# STM32MP13xx register map
File version: 1.5
CPU: CA7 r0p0, little endian, MPU, FPU, 4 interrupt priority bits
Registers are 32-bit, read-write, reset 0x0 unless marked. A register's access mark holds for its fields unless they carry their own. Offsets are from the block's base; [hi:lo] are bit positions; {n}, {i} and the like mark numbered series; 'fields as' and 'values as' point back to an identical list.

## DDRPHYC (part 2 of 2)
Base 0x5A004000
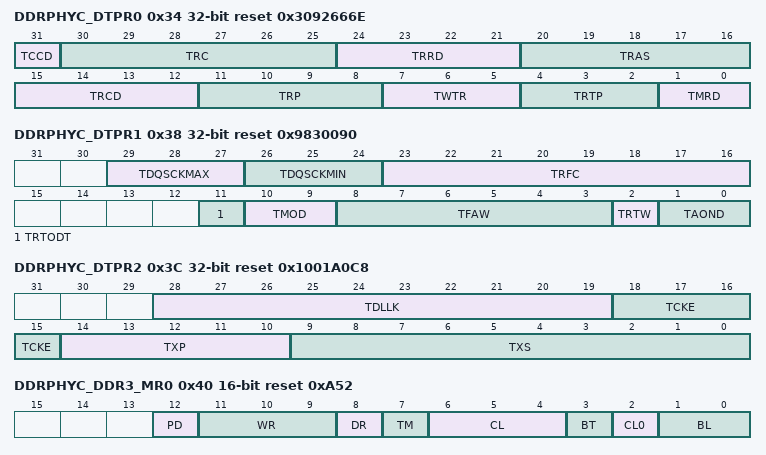
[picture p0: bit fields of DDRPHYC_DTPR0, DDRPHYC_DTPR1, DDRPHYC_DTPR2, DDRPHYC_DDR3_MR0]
0x34 DDRPHYC_DTPR0 reset 0x3092666E — DDRPHYC DTP register 0
  [31] TCCD — tCCDRead to read and write to write command delay
    0=BL/2 for DDR2 and 4 for DDR3; 1=BL/2 + 1 for DDR2 and 5 for DDR3
  [30:25] TRC — tRC Activate to activate command delay (same bank). Valid values are 2 to 42.
  [24:21] TRRD — tRRD Activate to activate command delay (different banks). Valid values are 1 to 8.
  [20:16] TRAS — tRAS Activate to precharge command delay. Valid values are 2 to 31.
  [15:12] TRCD — tRCD Activate to read or write delay. Minimum time from when an activate command is issued to when a read or write to the activated row can be issued. Valid values are 2 to 11.
  [11:8] TRP — tRP Precharge command period: The minimum time between a precharge command and any other command. Note: Note that the controller automatically derives tRPA for 8-bank DDR2 devices by adding 1 to tRP. Valid values are 2 to 11.
  [7:5] TWTR — tWTR Internal write to read command delay. Valid values are 1 to 6.
  [4:2] TRTP — tRTP Internal read to precharge command delay. Valid values are 2 to 6. Note that even though RTP does not apply to JEDEC DDR devices, this parameter must still be set to a minimum value of 2 for DDR because the Controller always uses the DDR2 equation, AL + BL/2 + max(RTP,2) â 2, to compute the read to precharge timing (which is BL/2 for JEDEC DDR).
  [1:0] TMRD — tMRD Load mode cycle time: The minimum time between a load mode register command and any other command. For DDR3 this is the minimum time between two load mode register commands. For DDR3, the value used for tMRD is 4 plus the value programmed in these bits, i.e. tMRD value for DDR3 ranges from 4 to 7. For LPDDR3, the value used for tMRD is 8 plus the value programmed in these bits.
0x38 DDRPHYC_DTPR1 reset 0x9830090 — DDRPHYC DTP register 1
  [29:27] TDQSCKMAX — tDQSCKmax Maximum DQS output access time from CK/CK# (LPDDR2 only). This value is used for implementing read-to-write spacing. Valid values are 1 to 7.
  [26:24] TDQSCKMIN — tDQSCKmin DQS output access time from CK/CK# (LPDDR2/3 only). This value is used for computing the read latency. Valid values are 0 to 7. This value is derived from the corresponding parameter in the SDRAM datasheet divided by the clock cycle time without rounding up. The fractional remainder is automatically adjusted for by data training in quarter clock cycle units. If data training is not performed then this fractional remainder must be converted to quarter clock cycle units and the gating registers (DXnDQSTR) adjusted accordingly.
  [23:16] TRFC — tRFC Refresh-to-Refresh: Indicates the minimum time, in clock cycles, between two refresh commands or between a refresh and an active command. This is derived from the minimum refresh interval from the datasheet, tRFC(min), divided by the clock cycle time. The default number of clock cycles is for the largest JEDEC tRFC(min parameter value supported.
  [11] TRTODT — tRTODT Read to ODT delay (DDR3 only). Specifies whether ODT can be enabled immediately after the read post-amble or one clock delay has to be added. Valid values are: If tRTODT is set to 1, then the read-to-write latency is increased by 1 if ODT is enabled.
    0=ODT may be turned on immediately after read post-amble; 1=ODT may not be turned on until one clock after the read post-amble
  [10:9] TMOD — tMOD Load mode update delay (DDR3 only). The minimum time between a load mode register command and a non-load mode register command. Valid values are:
    {v}={v+12} (v=0..3)
  [8:3] TFAW — tFAW 4-bank activate period. No more than 4-bank activate commands may be issued in a given tFAW period. Only applies to 8-bank devices. Valid values are 2 to 31.
  [2] TRTW — tRTW Read to Write command delay. Valid values are: This parameter allows the user to increase the delay between issuing Write commands to the SDRAM when preceded by Read commands. This provides an option to increase bus turn-around margin for high frequency systems.
    0=standard bus turn around delay; 1=add 1 clock to standard bus turn around delay
  [1:0] TAOND — tAOND/tAOFD ODT turn-on/turn-off delays (DDR2 only). The delays are in clock cycles. Valid values are: Most DDR2 devices utilize a fixed value of 2/2.5. For non-standard SDRAMs, the user must ensure that the operational Write Latency is always greater than or equal to the ODT turn-on delay. For example, a DDR2 SDRAM with CAS latency set to 3 and CAS additive latency set to 0 has a Write Latency of 2. Thus 2/2.5 can be used, but not 3/3.5 or higher.
    0=2/2.5; 1=3/3.5; 2=4/4.5; 3=5/5.5
0x3C DDRPHYC_DTPR2 reset 0x1001A0C8 — DDRPHYC DTP register 2
  [28:19] TDLLK — tDLLK DLL locking time. Valid values are 2 to 1023.
  [18:15] TCKE — tCKE CKE minimum pulse width. Also specifies the minimum time that the SDRAM must remain in power down or self refresh mode. For DDR3 this parameter must be set to the value of tCKESR which is usually bigger than the value of tCKE. Valid values are 2 to 15.
  [14:10] TXP — tXP Power down exit delay. The minimum time between a power down exit command and any other command. This parameter must be set to the maximum of the various minimum power down exit delay parameters specified in the SDRAM datasheet, i.e. max(tXP, tXARD, tXARDS) for DDR2 and max(tXP, tXPDLL) for DDR3. Valid values are 2 to 31.
  [9:0] TXS — tXS Self refresh exit delay. The minimum time between a self refresh exit command and any other command. This parameter must be set to the maximum of the various minimum self refresh exit delay parameters specified in the SDRAM datasheet, i.e. max(tXSNR, tXSRD) for DDR2 and max(tXS, tXSDLL) for DDR3. Valid values are 2 to 1023.
0x40 DDRPHYC_DDR3_MR0 16-bit reset 0xA52 — DDRPHYC MR0 register for DDR3
  [12] PD — Power-down control Controls the exit time for power-down modes. Refer to SDRAM datasheet for details on power-down modes. Valid values are:
    0=Slow exit (DLL off); 1=Fast exit (DLL on)
  [11:9] WR — Write recovery This is the value of the write recovery in clock cycles. It is calculated by dividing the data sheet write recovery time, tWR (ns) by the data sheet clock cycle time, tCK (ns) and rounding up a non-integer value to the next integer. Valid values are: All other settings are reserved and should not be used. Note: tWR (ns) is the time from the first SDRAM positive clock edge after the last data-in pair of a write command, to when a precharge of the same bank can be issued.
    {v}={v+4} (v=1..4); 5=10; 6=12
  [8] DR — DLL reset (autoclear) Writing a '1â to this bit resets the SDRAM DLL. This bit is self clearing, i.e. it returns back to '0â after the DLL reset has been issued.
  [7] TM — Operating mode Selects either normal operating mode (0) or test mode (1). Test mode is reserved for the manufacturer and should not be used.
  [6:4] CL — CAS latency The delay, in clock cycles, between when the SDRAM registers a read command to when data is available. Valid values for CL[3:0] are: Others: Reserved
  [3] BT — Burst type Indicates whether a burst is sequential (0) or interleaved (1).
  [2] CL0 — CAS latency The delay, in clock cycles, between when the SDRAM registers a read command to when data is available. Valid values for CL[3:0] are: Others: Reserved
  [1:0] BL — Burst length Determines the maximum number of column locations that can be accessed during a given read or write command. Valid values for DDR3 are:
    0=8 (Fixed); 1=4 or 8 (On the fly); 2=4 (Fixed)
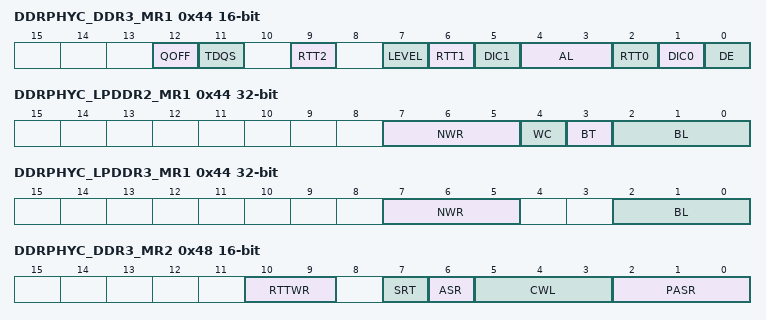
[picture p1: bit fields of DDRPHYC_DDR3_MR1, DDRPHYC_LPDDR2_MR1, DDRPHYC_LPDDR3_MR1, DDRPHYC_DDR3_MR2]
0x44 DDRPHYC_DDR3_MR1 16-bit — DDRPHYC MR1 register for DDR3
  [12] QOFF — Output enable/disable This feature is intended to be used for IDD characterization of read current and should not be used in normal operation.
    0=all outputs function as normal; 1=all SDRAM outputs are disabled removing output buffer current
  [11] TDQS — Termination data strobe When enabled ('1â) TDQS provides additional termination resistance outputs that may be useful in some system configurations. (N/A)
  [9] RTT2 — On die termination Selects the effective resistance for SDRAM on die termination. Valid values for {RTT2,RTT1,RTT0} are: Others: Reserved
  [7] LEVEL — Write leveling enable (N/A)
  [6] RTT1 — On die termination Selects the effective resistance for SDRAM on die termination. Valid values for {RTT2,RTT1,RTT0} are: Others: Reserved
  [5] DIC1 — Output driver impedance control Controls the output drive strength. Valid values for {DIC1,DIC0} are:
    0=RZQ/6; 1=RZQ/7
  [4:3] AL — Posted CAS Additive Latency: Setting additive latency that allows read and write commands to be issued to the SDRAM earlier than normal (refer to SDRAM datasheet for details). Valid values are:
    0=0 (AL disabled); 1=CL - 1; 2=CL - 2
  [2] RTT0 — On die termination Selects the effective resistance for SDRAM on die termination. Valid values for {RTT2,RTT1,RTT0} are: Others: Reserved
  [1] DIC0 — Output driver impedance control Controls the output drive strength. Valid values for {DIC1,DIC0} are:
    0=RZQ/6; 1=RZQ/7
  [0] DE — DLL enable/disable Enable (0) or disable (1) the DLL. DLL must be enabled for normal operation.
0x44 DDRPHYC_LPDDR2_MR1 (alternate view of DDRPHYC_DDR3_MR1)
  [7:5] NWR — Write recovery Others: Reserved
    1=nWR=3; 4=nWR=6; 6=nWR=8; 7=nWR=9
  [4] WC — Wrap control
    0=wrap; 1=no wrap
  [3] BT — Burst Type: Indicates whether a burst is sequential (0) or interleaved (1). ,
  [2:0] BL — Burst length Determines the maximum number of column locations that can be accessed during a given read or write command. Valid values are: Others: Reserved
    2=4; 3=8; 4=16
0x44 DDRPHYC_LPDDR3_MR1 (alternate view of DDRPHYC_DDR3_MR1)
  [7:5] NWR — Write recovery If nWRE (MR2 [4]) = 0: -001: nWR=3 -100: nWR=6 -110: nWR=8 -111: nWR=9 If nWRE (MR2[4]) = 1: -000: nWR=10 -001: nWR=11 -010: nWR=12 Others: Reserved
  [2:0] BL — Burst length Determines the maximum number of column locations that can be accessed during a given read or write command. Others: Reserved
    3=8
0x48 DDRPHYC_DDR3_MR2 16-bit — DDRPHYC MR2 register for DDR3
  [10:9] RTTWR — Dynamic ODT Selects RTT for dynamic ODT.
    0=Dynamic ODT off; 1=RZQ/4; 2=RZQ/2
  [7] SRT — Self-refresh temperature range Selects either normal ('0â) or extended ('1â) operating temperature range during self-refresh.
  [6] ASR — Auto self-refresh When enabled ('1â), SDRAM automatically provides self-refresh power management functions for all supported operating temperature values. Otherwise the SRT bit must be programmed to indicate the temperature range.
  [5:3] CWL — CAS write latency The delay, in clock cycles, between when the SDRAM registers a write command to when write data is available. Others: Reserved
    0=5 (tCK = 2.5ns); 1=6 (2.5ns > tCK = 1.875ns); 2=7 (1.875ns > tCK = 1.5ns); 3=8 (1.5ns > tCK = 1.25ns)
  [2:0] PASR — Partial array self-refresh Specifies that data located in areas of the array beyond the specified location are lost if self refresh is entered. Valid settings for 8 banks are:
    0=Full Array; 1=Half Array (BA[2:0] = 000, 001, 010 & 011); 2=Quarter Array (BA[2:0] = 000, 001); 3=1/8 Array (BA[2:0] = 000); 4=3/4 Array (BA[2:0] = 010, 011, 100, 101, 110 & 111); 5=Half Array (BA[2:0] = 100, 101, 110 & 111); 6=Quarter Array (BA[2:0] = 110 & 111); 7=1/8 Array (BA[2:0] 111)
0x48 DDRPHYC_LPDDR2_MR2 (alternate view of DDRPHYC_DDR3_MR2) — DDRPHYC MR2 register for LPDDR2
  [2:0] RLWL — Read and write latency Others: Reserved
    1=RL = 3 /WL = 1; 2=RL = 4 / WL = 2; 3=RL = 5 / WL = 2; 4=RL = 6 / WL = 3; 5=RL = 7 / WL = 4; 6=RL = 8 / WL = 4
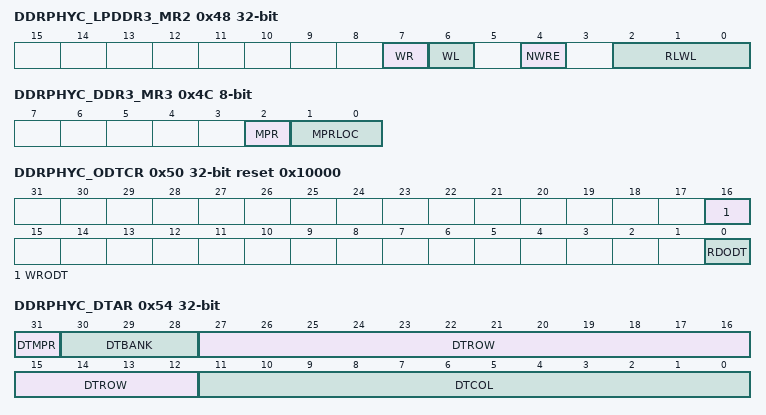
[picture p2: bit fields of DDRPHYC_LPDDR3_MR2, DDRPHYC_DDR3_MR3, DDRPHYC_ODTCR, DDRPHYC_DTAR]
0x48 DDRPHYC_LPDDR3_MR2 (alternate view of DDRPHYC_DDR3_MR2) — DDRPHYC MR2 register for LPDDR3
  [7] WR — New for LPDDR3 (not used by this PHY, leave at zero)
  [6] WL — New for LPDDR3 (not used by this PHY, leave at zero)
  [4] NWRE — New for LPDDR3 (not used by this PHY, leave at zero)
  [2:0] RLWL — Read and write latency Others: Reserved
    values as DDRPHYC_LPDDR2_MR2.RLWL
0x4C DDRPHYC_DDR3_MR3 8-bit — DDRPHYC MR3 register for DDR3
  [2] MPR — Multi-purpose register enable Enables, if set, that read data should come from the Multi-Purpose Register. Otherwise read data come from the DRAM array.
  [1:0] MPRLOC — Multi-purpose register (MPR) location Selects MPR data location. Others: Reserved
    0=Predefined pattern for system calibration
0x50 DDRPHYC_ODTCR reset 0x10000 — DDRPHYC ODTC register
  [16] WRODT — Specifies whether ODT should be enabled ('1â) or disabled ('0â) on write
  [0] RDODT — Specifies whether ODT should be enabled ('1â) or disabled ('0â) on read
0x54 DDRPHYC_DTAR — DDRPHYC DTA register
  [31] DTMPR — Data training using MPR (DDR3 Only): Specifies, if set, that data-training should use the SDRAM Multi-Purpose Register (MPR) register. Otherwise data-training is performed by first writing to some locations in the SDRAM and then reading the back.
  [30:28] DTBANK — Data training bank address: Selects the SDRAM bank address to be used during data training.
  [27:12] DTROW — Data training row address: Selects the SDRAM row address to be used during data training.
  [11:0] DTCOL — Data training column address: Selects the SDRAM column address to be used during data training. The lower four bits of this address must always be â0000â.
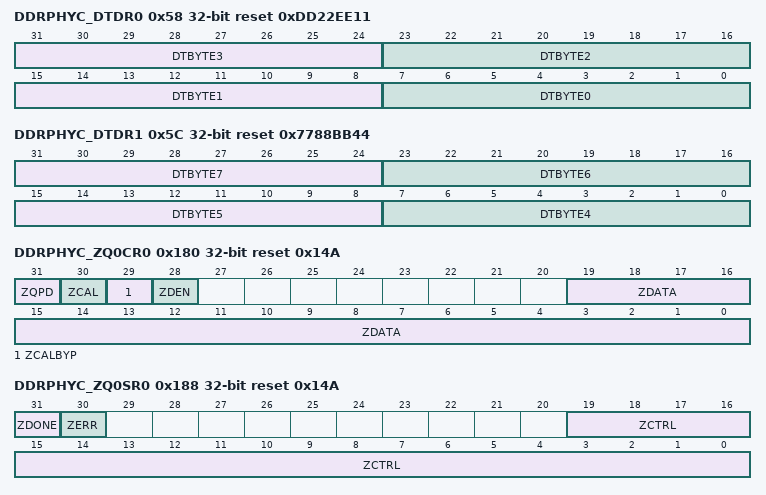
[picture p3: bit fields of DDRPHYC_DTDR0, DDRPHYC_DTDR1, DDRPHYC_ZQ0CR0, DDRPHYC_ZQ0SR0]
0x58 DDRPHYC_DTDR0 reset 0xDD22EE11 — DDRPHYC DTD register 0
  [31:24] DTBYTE3 — Data training data The first 4 bytes (e.g. shifted as Byte 0,1,2,3) of data used during data training. This same data byte is used for each Byte Lane. Default sequence is a walking 1 while toggling data every data cycle.
  [23:16] DTBYTE2 — Data Training Data
  [15:8] DTBYTE1 — Data Training Data
  [7:0] DTBYTE0 — Data Training Data
0x5C DDRPHYC_DTDR1 reset 0x7788BB44 — DDRPHYC DTD register 1
  [31:24] DTBYTE7 — Data training data: The second 4 bytes (e.g. shifted as Byte 4,5,6,7) of data used during data training. This same data byte is used for each Byte Lane. Default sequence is a walking 1 while toggling data every data cycle.
  [23:16] DTBYTE6 — Data Training Data
  [15:8] DTBYTE5 — Data Training Data
  [7:0] DTBYTE4 — Data Training Data
0x178 DDRPHYC_GPR0 — DDRPHYC general purpose register 0
  [31:0] GPR0 — General purpose register 0 bits
0x17C DDRPHYC_GPR1 — DDRPHYC general purpose register 1
  [31:0] GPR1 — General purpose register 1 bits
0x180 DDRPHYC_ZQ0CR0 reset 0x14A — DDRPHYC ZQ0C register 0
  [31] ZQPD — ZCAL power down Powers down, if set, the PZQ cell.
  [30] ZCAL — ZCAL trigger Impedance Calibration Trigger: A write of '1' to this bit triggers impedance calibration to be performed by the impedance control logic. The impedance calibration trigger bit is self-clearing and returns back to '0' when the calibration is complete. Note: If ZDEN is set, then the ZCAL bit should be set to 0.
  [29] ZCALBYP — Impedance calibration bypass Impedance Calibration Bypass: Disables, if set, impedance calibration of this ZQ control block when impedance calibration is triggered globally using the ZCAL bit of DDRPHYC_PIR. Impedance calibration of this ZQ block may be triggered manually using ZCAL.
  [28] ZDEN — Impedance override enable Impedance Over-ride Enable: When this bit is set, it allows users to directly drive the impedance control using the data programmed in the ZQDATA field. Otherwise, the control is generated automatically by the impedance control logic. Note: If ZDEN is set, then the ZCAL bit should be set to 0.
  [19:0] ZDATA — Impedance override Impedance Over-Ride Data: Data used to directly drive the impedance control. ZDATA field mapping for D3R I/Os is as follows: ZDATA[27:20] is reserved and returns zeros on reads ZDATA[19:15] is used to select the pull-up on-die termination impedance ZDATA[14:10] is used to select the pull-down on-die termination impedance ZDATA[9:5] is used to select the pull-up output impedance ZDATA[4:0] is used to select the pull-down output impedance Note: See mPHY ST40c25 Datasheet for ZDATA encoding, default value is: ODT pulp-up/down set to hi-impedance and pull-up/down set to ~44.5Â â¦ for DDR3, 48.8Â â¦ for DDR3L, 55.5Â â¦ for LPDDR2 typical corner 25C
0x184 DDRPHYC_ZQ0CR1 8-bit reset 0x7B
  [7:0] ZPROG — Impedance divide ratio to ext R Impedance divide ratio: selects the external resistor divide ratio to be used to set the output impedance and the on-die termination as follows: nullÂ Î© Â±1%) - 0x0: Reserved - 0x1: 120Â Î© - 0x2: 96Â Î© - 0x3: 80Â Î© - 0x4: 69Â Î© - 0x5: 60Â Î© - 0x6: 52Î© - 0x7: 46Â Î© - 0x8: 40Â Î© - 0x9: 37Â Î© - 0xA: 34Â Î© - 0xB: 32Â Î© - 0xC: 30Â Î© - 0xD: 28Â Î© - 0xE: 26.5Â Î© - 0xF: 25Â Î© nullImpedance divide ratio to ext R Impedance divide ratio: selects the external resistor divide ratio to be used to set the output impedance and the on-die termination as follows: nullÂ Î© Â±1%) - 0x0 to 0x4: Reserved - 0x5: 80Â Î© - 0x6: 69Â Î© - 0x7: 60Â Î© - 0x8: 53Â Î© - 0x9: 48Â Î© - 0xA: 44Â Î© - 0xB: 40Â Î© - 0xC: 37Â Î© - 0xD: 34Â Î© - 0xE: 32Â Î© - 0xF: 30Â Î©
0x188 DDRPHYC_ZQ0SR0 ro reset 0x14A — DDRPHYC ZQ0S register 0
  [31] ZDONE — Impedance calibration done Indicates that impedance calibration has completed.
  [30] ZERR — Impedance calibration error If set, indicates that there was an error during impedance calibration.
  [19:0] ZCTRL — Impedance control Impedance Control: Current value of impedance control. ZZCTRL field mapping for D3R I/Os is as follows: ZCTRL[27:20] is reserved and returns zeros on reads ZCTRL[19:15] is used to select the pull-up on-die termination impedance ZCTRL[14:10] is used to select the pull-down on-die termination impedance ZCTRL[9:5] is used to select the pull-up output impedance ZCTRL[4:0] is used to select the pull-down output impedance
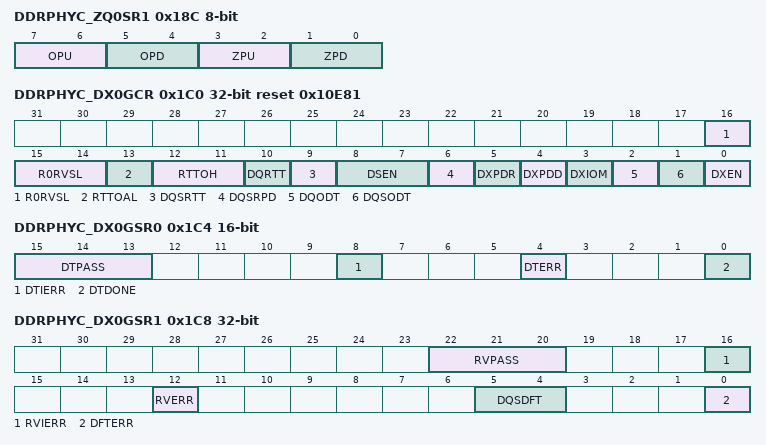
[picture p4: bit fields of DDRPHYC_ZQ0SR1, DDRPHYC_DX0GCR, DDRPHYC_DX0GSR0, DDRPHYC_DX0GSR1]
0x18C DDRPHYC_ZQ0SR1 8-bit ro — DDRPHYC ZQ0S register 1
  [all] fields
    0=Completed with no errors; 1=Overflow error; 2=Underflow error; 3=Calibration in progress
  [7:6] OPU — opu calibration status On-Die termination (ODT) pull-up calibration status.
  [5:4] OPD — opd calibration status On-Die termination (ODT) pull-down calibration status.
  [3:2] ZPU — zpu calibration status Output impedance pull-up calibration status. Valid status encodings are:
  [1:0] ZPD — zpd calibration status Output impedance pull-down calibration status. Valid status encodings are:
0x1C0 DDRPHYC_DX0GCR reset 0x10E81 — DDRPHYC byte lane 0 GC register
  [16:14] R0RVSL — Read valid system latency in steps Used to specify the read valid system latency relative to the ideal placement of the ITMD read valid signal when bit RVSEL in DDRPHYC_DXCCR register is set to 0. Power-up default is 011 (i.e. ideal placement of the read valid signal). The RVSL fields are initially set by the PUB during automatic read valid training but these values can be overwritten by a direct write to this register. Valid values are: Others: Reserved
    0=read valid system latency = ideal placement - 3; 1=read valid system latency = ideal placement - 2; 2=read valid system latency = ideal placement - 1; 3=read valid system latency = ideal placement; 4=read valid system latency = ideal placement + 1; 5=read valid system latency = ideal placement + 2; 6=read valid system latency = ideal placement + 3
  [13] RTTOAL — RTT ON additive latency Indicates when the ODT control of DQ/DQS SSTL I/Os is set to the value in DQODT/DQSODT during read cycles. Valid values are:
    0=ODT control is set to DQSODT/DQODT almost two cycles before read data preamble; 1=ODT control is set to DQSODT/DQODT almost one cycle before read data preamble
  [12:11] RTTOH — RTT output hold Indicates the number of clock cycles (from 0 to 3) after the read data postamble for which ODT control should remain set to DQSODT for DQS or DQODT for DQ/DM before disabling it (setting it to '0â) when using dynamic ODT control. ODT is disabled almost RTTOH clock cycles after the read postamble
  [10] DQRTT — DQ dynamic RTT control Indicates, if set, that the ODT control of DQ/DM SSTL I/Os be dynamically controlled by setting it to the value in DQODT during reads and disabling it (setting it to '0â) during any other cycle. If this bit is not set, then the ODT control of DQ SSTL I/Os is always set to the value in DQODT. Since dynamic ODT is on by default, when using LPDDR2/LPDDR3 this bit must be set to 0 since LPDDR2/LPDDR3 does not require ODT to be on.`
  [9] DQSRTT — DQS dynamic RTT control Indicates, if set, that the ODT control of DQS SSTL I/Os be dynamically controlled by setting it to the value in DQSODT during reads and disabling it (setting it to '0â) during any other cycle. If this bit is not set, then the ODT control of DQS SSTL I/Os is always set to the value in DQSODT field. Since dynamic ODT is on by default, when using LPDDR2/LPDDR3 this bit must be set to 0 since LPDDR2/LPDDR3 does not require ODT to be on.
  [8:7] DSEN — Write DQS enable Controls whether the write DQS going to the SDRAM is enabled (toggling) or disabled (static value) and whether the DQS is inverted. DQS# is always the inversion of DQS. These values are valid only when DQS/DQS# output enable is on, otherwise the DQS/DQS# is tristated. Valid settings are:
    0=DQS disabled (Driven to constant 0); 1=DQS toggling with normal polarity (This should be the default setting); 2=DQS toggling with inverted polarity; 3=DQS disabled (Driven to constant 1)
  [6] DQSRPD — DQSR power-down Powers down, if set, the PDQSR cell. This bit is ORed with the common PDR configuration bit
  [5] DXPDR — Data power-down receiver Powers down, when set, the input receiver on I/O for DQ, DM, and DQS/DQS# pins of the byte. This bit is ORed with the common PDR configuration bit
  [4] DXPDD — Data power-down driver Powers down, when set, the output driver on I/O for DQ, DM, and DQS/DQS# pins of the byte. This bit is ORed with the common PDD configuration bit
  [3] DXIOM — Data I/O mode Selects SSTL mode (when set to 0) or CMOS mode (when set to 1) for the I/O for DQ, DM, and DQS/DQS# pins of the byte. This bit is ORed with the IOM configuration bit of the individual DATX8
  [2] DQODT — DQ ODT enable Enables, when set, the on-die termination on the I/O for DQ and DM pins of the byte. This bit is ORed with the common DATX8 ODT configuration bit
  [1] DQSODT — DQS ODT enable Enables, when set, the on-die termination on the I/O for DQS/DQS# pin of the byte. This bit is ORed with the common DATX8 ODT configuration bit
  [0] DXEN — DATA byte enable Enables, if set, the DATX8 and SSTL I/Os used on the data byte. Setting this bit to '0â disables the byte, i.e. the byte SSTL I/Os are put in power-down mode and the DLL in the DATX8 is put in bypass mode. After changing a Byte Lane from disabled to enabled, the DLL for that Byte Lane must be reset and re-locked. Software can use bits DLLSRST and DLLLOCK of DDRPHYC_PIR register to accomplish this (reset and re-locks all DLLs in the DDR PHY).
0x1C4 DDRPHYC_DX0GSR0 16-bit ro — DDRPHYC byte lane 0 GS register 0
  [15:13] DTPASS — DQS training pass count The number of passing configurations during DQS gate training.
  [8] DTIERR — DQS gate training intermittent error If set, indicates that there was an intermittent error during DQS gate training of the byte, such as a pass was followed by a fail then followed by another pass.
  [4] DTERR — DQS gate training error If set, indicates that a valid DQS gating window could not be found during DQS gate training of the byte.
  [0] DTDONE — Data training done Indicates, if set, that the byte has finished doing data training.
0x1C8 DDRPHYC_DX0GSR1 ro — DDRPHYC byte lane 0 GS register 1
  [22:20] RVPASS — Read valid training pass count The number of passing configurations during read valid training.
  [16] RVIERR — RV intermittent error for rank If set, indicates that there was an intermittent error during read valid training of the byte, such as a pass was followed by a fail then followed by another pass.
  [12] RVERR — RV training error If set, indicates that a valid read valid placement could not be found during read valid training of the byte
  [5:4] DQSDFT — DQS drift value Used to report the drift on the read data strobe of the data byte. Valid settings are:
    0=No drift; 1=90Â° drift; 2=180Â° drift; 3=270Â° drift or more
  [0] DFTERR — DQS drift error If set, indicates that the byte read data strobe has drifted by more than or equal to the drift limit set in the PHY General Configuration Register (PGCR).
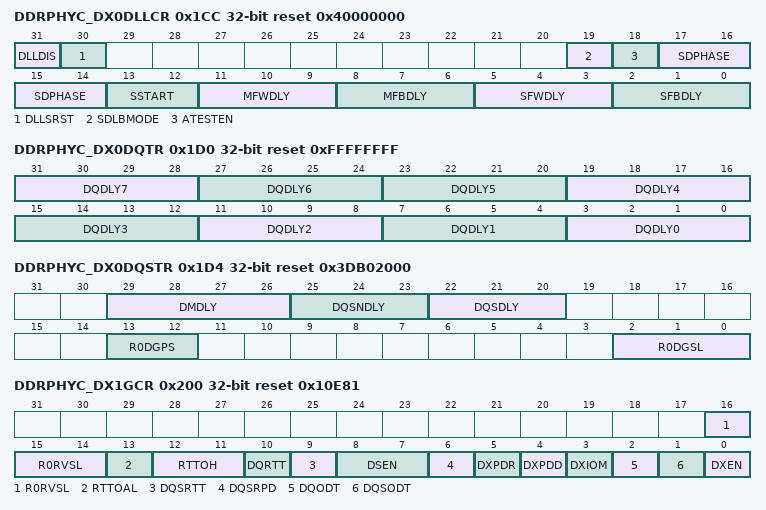
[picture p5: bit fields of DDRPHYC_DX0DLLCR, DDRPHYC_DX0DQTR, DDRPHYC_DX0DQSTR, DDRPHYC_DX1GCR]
0x1CC DDRPHYC_DX0DLLCR reset 0x40000000 — DDRPHYC byte lane 0 DLLC register
  [31] DLLDIS — DLL bypass A disabled DLL is bypassed. Default ('0') is DLL enabled
  [30] DLLSRST — DLL reset Soft resets the byte DLL by driving the DLL soft reset pin
  [19] SDLBMODE — Bypass slave DLL during loopback If this bit is set, the slave DLL is put in loopback mode in which there is no 90 degrees phase shift on read DQS/DQS#. This bit must be set when operating the byte PHYs in loopback mode.
  [18] ATESTEN — Enable path to pin 'ATO' Enables the analog test signal to be output on the DLL analog test output (test_out_a). The DLL analog test output is tri-stated when this bit is '0'.
  [17:14] SDPHASE — Slave DLL phase Selects the phase difference between the input clock and the corresponding output clock of the slave DLL. Valid settings:
    0=90; 1=72; 2=54; 3=36; 4=108; 5=90; 6=72; 7=54; 8=126; 9=108; 10=90; 11=72; 12=144; 13=126; 14=108; 15=90
  [13:12] SSTART — Slave DLL autostart Used to control how the slave DLL starts up relative to the master DLL locking: 0X: Slave DLL automatically starts up once the master DLL has achieved lock. disabled. enabled.
    2=The automatic startup of the slave DLL is disabled; the phase detector is; 3=The automatic startup of the slave DLL is disabled; the phase detector is
  [11:9] MFWDLY — Master DLL feed-forward trim Used to trim the delay in the master DLL feedforward path: ...
    0=minimum delay; 7=maximum delay
  [8:6] MFBDLY — Master DLL feed-back trim Used to trim the delay in the master DLL feedback path: ...
    0=minimum delay; 7=maximum delay
  [5:3] SFWDLY — Slave DLL feed-forward trim Slave Feed-Forward Delay Trim: Used to trim the delay in the slave DLL feedforward path: ...
    0=minimum delay; 7=maximum delay
  [2:0] SFBDLY — Slave DLL feed-back trim Slave Feed-Back Delay Trim: Used to trim the delay in the slave DLL feedback path: ...
    0=minimum delay; 7=maximum delay
0x1D0 DDRPHYC_DX0DQTR reset 0xFFFFFFFF — DDRPHYC byte lane 0 DQT register
  [31:28] DQDLY7 — DQ delay for bit 7 Used to adjust the delay of the data relative to the nominal delay that is matched to the delay of the data strobes through the slave DLL and clock tree. The lower two bits of the DQDLY for each DQ bit controls the delay for the data clocked by DQS, while the higher two bits control the delay for the data clocked by DQS_b. Valid settings for each 2-bit control field are:
    0=nominal delay; 1=nominal delay + 1 step; 2=nominal delay + 2 steps; 3=nominal delay + 3 steps
  [27:24] DQDLY6 — DQ delay for bit 6 idem
  [4n+3:4n] DQDLY{n} (n=0..5) — DQ delay for bit {n} Idem
0x1D4 DDRPHYC_DX0DQSTR reset 0x3DB02000 — DDRPHYC byte lane 0 DQST register
  [29:26] DMDLY — DM delay Used to adjust the delay of the data relative to the nominal delay that is matched to the delay of the data strobes through the slave DLL and clock tree. The lower two bits of the DQDLY for each DQ bit controls the delay for the data clocked by DQS, while the higher two bits control the delay for the data clocked by DQS_b. Valid settings for each 2-bit control field are:
    values as DDRPHYC_DX0DQTR.DQDLY7
  [25:23] DQSNDLY — DQS# delay Used to adjust the delay of the data strobes relative to the nominal delay that is matched to the delay of the data bit through the slave DLL and clock tree. Valid values are: Note: - After changing this value, an ITM soft reset must be issued: bit ITMSRST=1 and bit INIT=1 in DDRPHYC_PIR register.
    0=nominal delay - 3 steps; 1=nominal delay - 2 steps; 2=nominal delay - 1 step; 3=nominal delay; 4=nominal delay + 1 step; 5=nominal delay + 2 steps; 6=nominal delay + 3 steps; 7=nominal delay + 4 steps
  [22:20] DQSDLY — DQS delay Used to adjust the delay of the data strobes relative to the nominal delay that is matched to the delay of the data bit through the slave DLL and clock tree. Valid values are: Note: - After changing this value, an ITM soft reset (bit ITMSRST=1 and bit INIT=1 in DDRPHYC_PIR register) must be issued.
    values as DQSNDLY
  [13:12] R0DGPS — Rank 0 DQS gating phase select Selects the clock used to enable the data strobes during read so that the value of the data strobes before and after the preamble/postamble are filtered out. R0DGPS is initially set by the PUBL during automatic DQS data training and subsequently updated during data strobe drift compensation. However, these values can be overwritten by a direct write to this register, and the automatic update during DQS drift compensation can be disabled using the PHY General Configuration Register (PGCR). Valid values are:
    0=180 clock (clk180); 1=270 clock (clk270); 2=360 clock (clk0); 3=450 clock (next clk90)
  [2:0] R0DGSL — Rank 0 DQS gating system latency Used to increase the number of clock cycles needed to expect valid DDR read data by up to five extra clock cycles. This is used to compensate for board delays and other system delays. Power-up default is 000 (i.e. no extra clock cycles required). The SL fields are initially set by the PUBL during automatic DQS data training but these values can be overwritten by a direct write to this register. Valid values are: Others: Reserved
    0=No extra clock cycles; 1=1 extra clock cycle; {v}={v} extra clock cycles (v=2..5)
0x200 DDRPHYC_DX1GCR reset 0x10E81 — DDRPHYC byte lane 1 GC register
  fields as DDRPHYC_DX0GCR
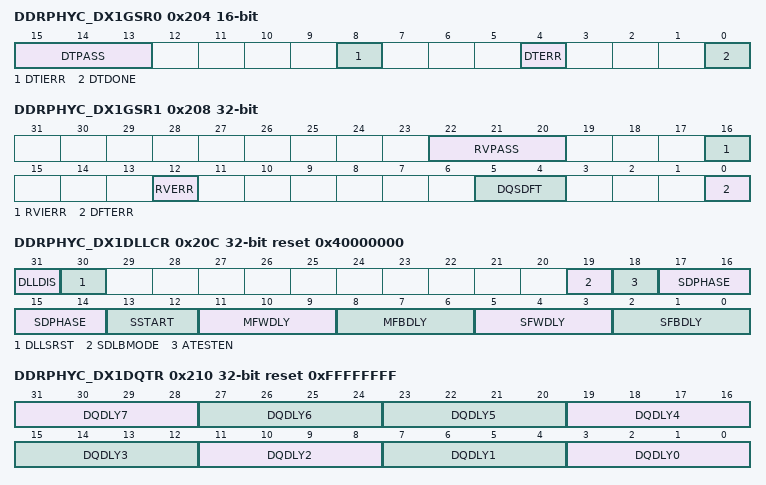
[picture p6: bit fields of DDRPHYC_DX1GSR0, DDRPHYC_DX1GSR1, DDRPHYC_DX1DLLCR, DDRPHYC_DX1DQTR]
0x204 DDRPHYC_DX1GSR0 16-bit ro — DDRPHYC byte lane 1 GS register 0
  fields as DDRPHYC_DX0GSR0
0x208 DDRPHYC_DX1GSR1 ro — DDRPHYC byte lane 1 GS register 1
  fields as DDRPHYC_DX0GSR1
0x20C DDRPHYC_DX1DLLCR reset 0x40000000 — DDRPHYC byte lane 1 DLLC register
  fields as DDRPHYC_DX0DLLCR
0x210 DDRPHYC_DX1DQTR reset 0xFFFFFFFF — DDRPHYC byte lane 1 DQT register
  fields as DDRPHYC_DX0DQTR
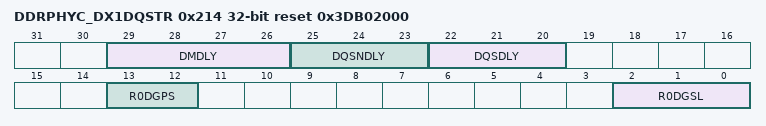
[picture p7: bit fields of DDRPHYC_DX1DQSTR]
0x214 DDRPHYC_DX1DQSTR reset 0x3DB02000 — DDRPHYC byte lane 1 DQST register
  fields as DDRPHYC_DX0DQSTR
